AUTOSAR XML (schema 00053)
standard types defined: uint16
package /DataTypes
  impl type IDT: category=VALUE, base-type=uint16
package /SWA
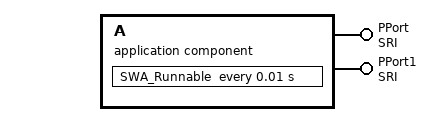
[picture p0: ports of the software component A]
  application sw component type A
    provide port PPort: provided-interface=SRI
    provide port PPort1: provided-interface=SRI
    behavior InternalBehavior
      timing event SWA_TEvent: start-on-event=SWA_Runnable, period=0.01
      runnable SWA_Runnable: symbol=A_SWA_Runnable
        data-write-access:
          access DWA_PPort_E1: accessed-variable=PPort.E1
          access DWA_PPort1_E1: accessed-variable=PPort1.E1
  application sw component type B
    require port RPort: required-interface=SRI
    behavior InternalBehavior
  composition sw component type RootComposition
    component A: type=A
    component B: type=B
    connect A.PPort -> B.RPort
  sender receiver interface SRI
    data E1: type=IDT
  swc implementation SwcImplementation: programming-language=C, sw-version=1.0.0.0, behavior=A/InternalBehavior
    code-descriptors:
      code CodeDescriptor: artifact-descriptors=autosar-engineering-object={short-label=A_AppSw.c, category=SWSRC}
    resource consumption ResourceConsumption
